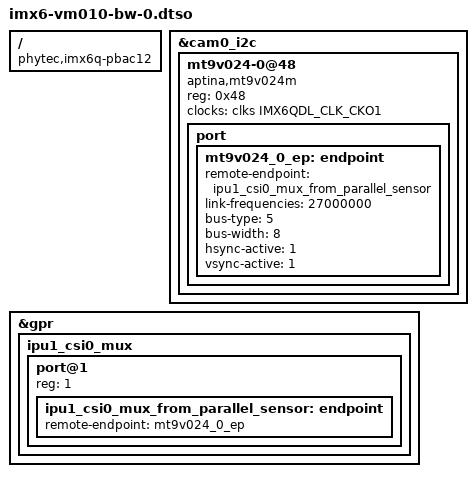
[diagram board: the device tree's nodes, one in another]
// SPDX-License-Identifier: (GPL-2.0+ OR MIT)
/*
 * Copyright (C) 2021 PHYTEC Messtechnik GmbH
 * Author: Stefan Riedmueller <s.riedmueller@phytec.de>
 */

/dts-v1/;
/plugin/;

#include <dt-bindings/clock/imx6qdl-clock.h>

/ {
	compatible = "phytec,imx6q-pbac12", "phytec,imx6dl-pbac12",
		     "phytec,imx6q-pbac06", "phytec,imx6dl-pbac06",
		     "phytec,imx6q-pbab01", "phytec,imx6dl-pbab01";
};

&cam0_i2c {
	#address-cells = <1>;
	#size-cells = <0>;

	mt9v024-0@48 {
		compatible = "aptina,mt9v024m";
		reg = <0x48>;

		clocks = <&clks IMX6QDL_CLK_CKO1>;

		port {
			mt9v024_0_ep: endpoint {
				remote-endpoint = <&ipu1_csi0_mux_from_parallel_sensor>;
				link-frequencies = /bits/ 64 <27000000>;
				bus-type = <5>; /* Parallel */
				bus-width = <8>;
				hsync-active = <1>;
				vsync-active = <1>;
			};
		};
	};
};

&gpr {
	ipu1_csi0_mux {
		#address-cells = <1>;
		#size-cells = <0>;

		port@1 {
			reg = <1>;
			ipu1_csi0_mux_from_parallel_sensor: endpoint {
				remote-endpoint = <&mt9v024_0_ep>;
			};
		};
	};
};
